# STM32H533xx register map
File version: 1.0
Registers are 32-bit, read-write, reset 0x0 unless marked. A register's access mark holds for its fields unless they carry their own. Offsets are from the block's base; [hi:lo] are bit positions.

## RSSLIB_PFUNC — RSSLib function pointer structure
Base 0x0BF9FB68
0x00 DataProvisioning ro
0x10 JumpHDPLvl2 ro
0x14 JumpHDPLvl3 ro
0x18 JumpHDPLvl3NS ro

## NSSLIB_PFUNC — RSSLib secure callable function pointer structure
Base 0x0BF9FB6C
0x00 JumpHDPLvl2 ro
0x04 JumpHDPLvl3 ro

## WWDG
Base 0x40002C00
Same registers: WWDG_S 0x50002C00
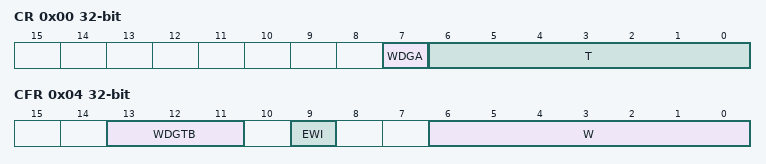
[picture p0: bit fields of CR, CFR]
0x00 CR — WWDG Control register
  [7] WDGA — Activation bit
  [6:0] T — T[6:0] bits (7-Bit counter (MSB to LSB))
0x04 CFR — WWDG Configuration register
  [13:11] WDGTB — WDGTB[2:0] bits (Timer Base)
    0=PRESCALER_1 (WWDG counter clock = (PCLK1/4096)/1); 1=PRESCALER_2 (WWDG counter clock = (PCLK1/4096)/2); 2=PRESCALER_4 (WWDG counter clock = (PCLK1/4096)/4); 3=PRESCALER_8 (WWDG counter clock = (PCLK1/4096)/8); 4=PRESCALER_16 (WWDG counter clock = (PCLK1/4096)/16); 5=PRESCALER_32 (WWDG counter clock = (PCLK1/4096)/32); 6=PRESCALER_64 (WWDG counter clock = (PCLK1/4096)/64); 7=PRESCALER_128 (WWDG counter clock = (PCLK1/4096)/128)
  [9] EWI — Early Wakeup Interrupt
  [6:0] W — W[6:0] bits (7-bit window value)
0x08 SR — WWDG Status register
  [0] EWIF — Early Wakeup Interrupt Flag

## IWDG
Base 0x40003000
Same registers: IWDG_S 0x50003000
0x00 KR — IWDG Key register
  [15:0] KEY — Key value (write only, read 0000h)
0x04 PR — IWDG Prescaler register
  [3:0] PR — PR[3:0] (Prescaler divider)
0x08 RLR — IWDG Reload register
  [11:0] RL — Watchdog counter reload value
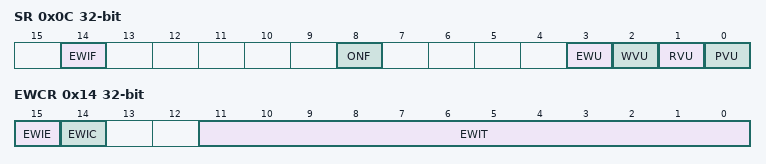
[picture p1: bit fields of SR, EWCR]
0x0C SR — IWDG Status register
  [14] EWIF — Watchdog early interrupt flag
  [8] ONF — Watchdog Enable status bit
  [3] EWU — Watchdog interrupt comparator value update
  [2] WVU — Watchdog counter window value update
  [1] RVU — Watchdog counter reload value update
  [0] PVU — Watchdog prescaler value update
0x10 WINR — IWDG Window register
  [11:0] WIN — Watchdog counter window value
0x14 EWCR — IWDG Early Wakeup register
  [15] EWIE — Watchdog early wakeup comparator value
  [14] EWIC — Watchdog early wakeup comparator value
  [11:0] EWIT — Watchdog early wakeup comparator value

## CRS — Clock Recovery System
Base 0x40006000
Same registers: CRS_S 0x50006000
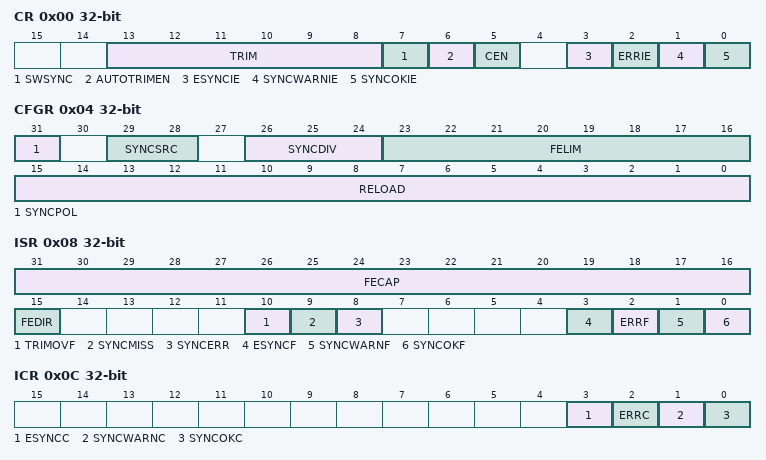
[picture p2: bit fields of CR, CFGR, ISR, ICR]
0x00 CR — CRS ccontrol register
  [13:8] TRIM — HSI48 oscillator smooth trimming
  [7] SWSYNC — Generate software SYNC event
  [6] AUTOTRIMEN — Automatic trimming enable
  [5] CEN — Frequency error counter enable
  [3] ESYNCIE — Expected SYNC interrupt enable
  [2] ERRIE — SYNC error or trimming error interrupt enable
  [1] SYNCWARNIE — SYNC warning interrupt enable
  [0] SYNCOKIE — SYNC event OK interrupt enable
0x04 CFGR — CRS configuration register
  [31] SYNCPOL — SYNC polarity selection
    0=RISING (Synchro Active on rising edge (default)); 1=FALLING (Synchro Active on falling edge)
  [29:28] SYNCSRC — SYNC signal source selection
    0=GPIO (Synchro Signal source GPIO); 1=LSE (Synchro Signal source LSE); 2=USB (Synchro Signal source USB SOF (default))
  [26:24] SYNCDIV — SYNC divider
    0=DIV_1 (Synchro Signal not divided (default)); 1=DIV_2 (Synchro Signal divided by 2); 2=DIV_4 (Synchro Signal divided by 4); 3=DIV_8 (Synchro Signal divided by 8); 4=DIV_16 (Synchro Signal divided by 16); 5=DIV_32 (Synchro Signal divided by 32); 6=DIV_64 (Synchro Signal divided by 64); 7=DIV_128 (Synchro Signal divided by 128)
  [23:16] FELIM — Frequency error limit
  [15:0] RELOAD — Counter reload value
0x08 ISR — CRS interrupt and status register
  [31:16] FECAP — Frequency error capture
  [15] FEDIR — Frequency error direction
    0=UP (Upcounting direction, the actual frequency is above the target); 1=DOWN (Downcounting direction, the actual frequency is below the target)
  [10] TRIMOVF — Trimming overflow or underflow
  [9] SYNCMISS — SYNC missed
  [8] SYNCERR — SYNC error
  [3] ESYNCF — Expected SYNC flag
  [2] ERRF — Error flag
  [1] SYNCWARNF — SYNC warning flag
  [0] SYNCOKF — SYNC event OK flag
0x0C ICR — CRS interrupt flag clear register
  [3] ESYNCC — Expected SYNC clear flag
  [2] ERRC — Error clear flag
  [1] SYNCWARNC — SYNC warning clear flag
  [0] SYNCOKC — SYNC event OK clear flag
